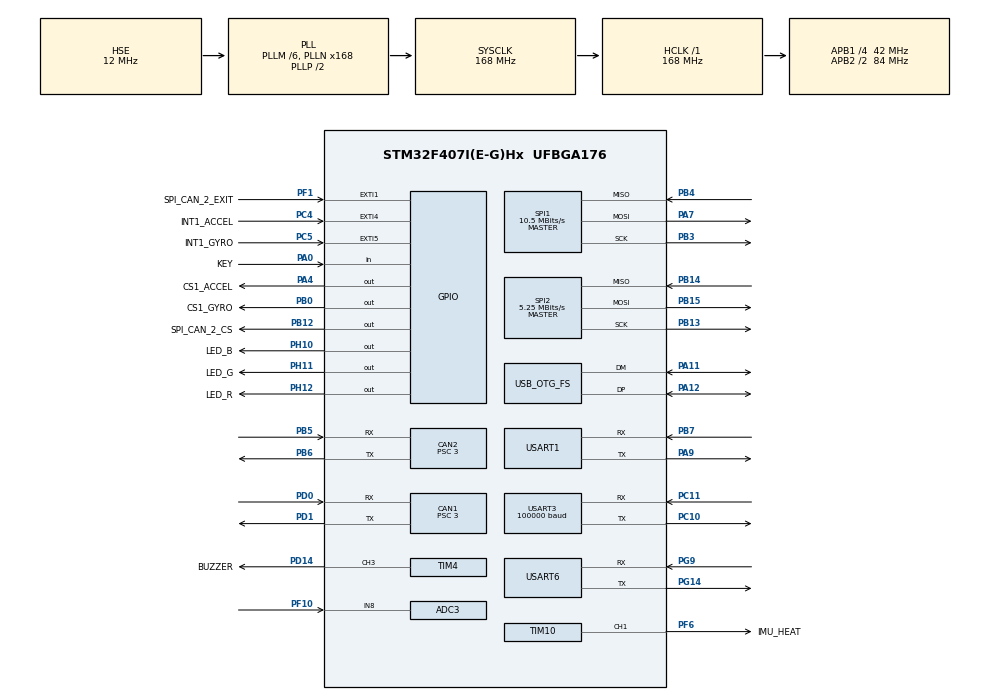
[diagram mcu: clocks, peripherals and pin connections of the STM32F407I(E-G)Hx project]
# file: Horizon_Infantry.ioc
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ADC1.Channel-0\#ChannelRegularConversion=ADC_CHANNEL_TEMPSENSOR
ADC1.NbrOfConversionFlag=1
ADC1.Rank-0\#ChannelRegularConversion=1
ADC1.SamplingTime-0\#ChannelRegularConversion=ADC_SAMPLETIME_3CYCLES
ADC1.master=1
ADC3.Channel-0\#ChannelRegularConversion=ADC_CHANNEL_8
ADC3.NbrOfConversionFlag=1
ADC3.Rank-0\#ChannelRegularConversion=1
ADC3.SamplingTime-0\#ChannelRegularConversion=ADC_SAMPLETIME_3CYCLES
CAN1.BS1=CAN_BS1_10TQ
CAN1.BS2=CAN_BS2_3TQ
CAN1.CalculateBaudRate=1000000
CAN1.CalculateTimeBit=1000
CAN1.CalculateTimeQuantum=71.42857142857143
CAN1.Prescaler=3
CAN2.BS1=CAN_BS1_10TQ
CAN2.BS2=CAN_BS2_3TQ
CAN2.CalculateBaudRate=1000000
CAN2.CalculateTimeBit=1000
CAN2.CalculateTimeQuantum=71.42857142857143
CAN2.Prescaler=3
Dma.Request0=SPI1_RX
Dma.Request1=SPI1_TX
Dma.Request2=USART1_RX
Dma.Request3=USART1_TX
Dma.Request4=USART6_RX
Dma.Request5=USART6_TX
Dma.Request6=TIM4_CH3
Dma.Request7=USART3_RX
Dma.SPI1_RX.0.Direction=DMA_PERIPH_TO_MEMORY
Dma.SPI1_RX.0.FIFOMode=DMA_FIFOMODE_DISABLE
Dma.SPI1_RX.0.Instance=DMA2_Stream2
Dma.SPI1_RX.0.MemDataAlignment=DMA_MDATAALIGN_BYTE
Dma.SPI1_RX.0.MemInc=DMA_MINC_ENABLE
Dma.SPI1_RX.0.Mode=DMA_NORMAL
Dma.SPI1_RX.0.PeriphDataAlignment=DMA_PDATAALIGN_BYTE
Dma.SPI1_RX.0.PeriphInc=DMA_PINC_DISABLE
Dma.SPI1_RX.0.Priority=DMA_PRIORITY_VERY_HIGH
Dma.SPI1_TX.1.Direction=DMA_MEMORY_TO_PERIPH
Dma.SPI1_TX.1.FIFOMode=DMA_FIFOMODE_DISABLE
Dma.SPI1_TX.1.Instance=DMA2_Stream3
Dma.SPI1_TX.1.MemDataAlignment=DMA_MDATAALIGN_BYTE
Dma.SPI1_TX.1.MemInc=DMA_MINC_ENABLE
Dma.SPI1_TX.1.Mode=DMA_NORMAL
Dma.SPI1_TX.1.PeriphDataAlignment=DMA_PDATAALIGN_BYTE
Dma.SPI1_TX.1.PeriphInc=DMA_PINC_DISABLE
Dma.SPI1_TX.1.Priority=DMA_PRIORITY_HIGH
Dma.TIM4_CH3.6.Direction=DMA_PERIPH_TO_MEMORY
Dma.TIM4_CH3.6.FIFOMode=DMA_FIFOMODE_DISABLE
Dma.TIM4_CH3.6.Instance=DMA1_Stream7
Dma.TIM4_CH3.6.MemDataAlignment=DMA_MDATAALIGN_HALFWORD
Dma.TIM4_CH3.6.MemInc=DMA_MINC_ENABLE
Dma.TIM4_CH3.6.Mode=DMA_NORMAL
Dma.TIM4_CH3.6.PeriphDataAlignment=DMA_PDATAALIGN_HALFWORD
Dma.TIM4_CH3.6.PeriphInc=DMA_PINC_DISABLE
Dma.TIM4_CH3.6.Priority=DMA_PRIORITY_LOW
Dma.USART1_RX.2.Direction=DMA_PERIPH_TO_MEMORY
Dma.USART1_RX.2.FIFOMode=DMA_FIFOMODE_DISABLE
Dma.USART1_RX.2.Instance=DMA2_Stream5
Dma.USART1_RX.2.MemDataAlignment=DMA_MDATAALIGN_BYTE
Dma.USART1_RX.2.MemInc=DMA_MINC_ENABLE
Dma.USART1_RX.2.Mode=DMA_NORMAL
Dma.USART1_RX.2.PeriphDataAlignment=DMA_PDATAALIGN_BYTE
Dma.USART1_RX.2.PeriphInc=DMA_PINC_DISABLE
Dma.USART1_RX.2.Priority=DMA_PRIORITY_LOW
Dma.USART1_TX.3.Direction=DMA_MEMORY_TO_PERIPH
Dma.USART1_TX.3.FIFOMode=DMA_FIFOMODE_DISABLE
Dma.USART1_TX.3.Instance=DMA2_Stream7
Dma.USART1_TX.3.MemDataAlignment=DMA_MDATAALIGN_BYTE
Dma.USART1_TX.3.MemInc=DMA_MINC_ENABLE
Dma.USART1_TX.3.Mode=DMA_NORMAL
Dma.USART1_TX.3.PeriphDataAlignment=DMA_PDATAALIGN_BYTE
Dma.USART1_TX.3.PeriphInc=DMA_PINC_DISABLE
Dma.USART1_TX.3.Priority=DMA_PRIORITY_LOW
Dma.USART3_RX.7.Direction=DMA_PERIPH_TO_MEMORY
Dma.USART3_RX.7.FIFOMode=DMA_FIFOMODE_DISABLE
Dma.USART3_RX.7.Instance=DMA1_Stream1
Dma.USART3_RX.7.MemDataAlignment=DMA_MDATAALIGN_BYTE
Dma.USART3_RX.7.MemInc=DMA_MINC_ENABLE
Dma.USART3_RX.7.Mode=DMA_NORMAL
Dma.USART3_RX.7.PeriphDataAlignment=DMA_PDATAALIGN_BYTE
Dma.USART3_RX.7.PeriphInc=DMA_PINC_DISABLE
Dma.USART3_RX.7.Priority=DMA_PRIORITY_LOW
Dma.USART6_RX.4.Direction=DMA_PERIPH_TO_MEMORY
Dma.USART6_RX.4.FIFOMode=DMA_FIFOMODE_DISABLE
Dma.USART6_RX.4.Instance=DMA2_Stream1
Dma.USART6_RX.4.MemDataAlignment=DMA_MDATAALIGN_BYTE
Dma.USART6_RX.4.MemInc=DMA_MINC_ENABLE
Dma.USART6_RX.4.Mode=DMA_NORMAL
Dma.USART6_RX.4.PeriphDataAlignment=DMA_PDATAALIGN_BYTE
Dma.USART6_RX.4.PeriphInc=DMA_PINC_DISABLE
Dma.USART6_RX.4.Priority=DMA_PRIORITY_LOW
Dma.USART6_TX.5.Direction=DMA_MEMORY_TO_PERIPH
Dma.USART6_TX.5.FIFOMode=DMA_FIFOMODE_DISABLE
Dma.USART6_TX.5.Instance=DMA2_Stream6
Dma.USART6_TX.5.MemDataAlignment=DMA_MDATAALIGN_BYTE
Dma.USART6_TX.5.MemInc=DMA_MINC_ENABLE
Dma.USART6_TX.5.Mode=DMA_NORMAL
Dma.USART6_TX.5.PeriphDataAlignment=DMA_PDATAALIGN_BYTE
Dma.USART6_TX.5.PeriphInc=DMA_PINC_DISABLE
Dma.USART6_TX.5.Priority=DMA_PRIORITY_LOW
FREERTOS.INCLUDE_eTaskGetState=1
FREERTOS.INCLUDE_pcTaskGetTaskName=1
FREERTOS.INCLUDE_uxTaskGetStackHighWaterMark=1
FREERTOS.INCLUDE_vTaskCleanUpResources=1
FREERTOS.INCLUDE_vTaskDelayUntil=1
FREERTOS.INCLUDE_xEventGroupSetBitFromISR=1
FREERTOS.INCLUDE_xQueueGetMutexHolder=1
FREERTOS.INCLUDE_xSemaphoreGetMutexHolder=1
FREERTOS.INCLUDE_xTaskAbortDelay=1
FREERTOS.INCLUDE_xTaskGetCurrentTaskHandle=1
FREERTOS.INCLUDE_xTaskGetHandle=1
FREERTOS.INCLUDE_xTimerPendFunctionCall=1
FREERTOS.Tasks01=defaultTask,0,128,StartDefaultTask,As weak,NULL,Dynamic,NULL,NULL;RobotUITask,-2,512,StartRobotUITask,As weak,NULL,Dynamic,NULL,NULL;MoveTask,2,512,StartMoveTask,As weak,NULL,Dynamic,NULL,NULL;DefiantTask,0,256,StartDefiantTask,As weak,NULL,Dynamic,NULL,NULL;IMUTask,2,512,StartIMUTask,As weak,NULL,Dynamic,NULL,NULL;RootTask,0,3072,StartRootTask,As weak,NULL,Dynamic,NULL,NULL
FREERTOS.configTOTAL_HEAP_SIZE=24576
FREERTOS.configUSE_TIMERS=1
Mcu.Family=STM32F4
Mcu.Name=STM32F407I(E-G)Hx
Mcu.Package=UFBGA176
NVIC.CAN1_RX0_IRQn=true\:5\:0\:false\:false\:true\:true\:true\:true\:true
NVIC.CAN2_RX0_IRQn=true\:5\:0\:false\:false\:true\:true\:true\:true\:true
NVIC.DMA1_Stream1_IRQn=true\:5\:0\:false\:false\:true\:true\:false\:true\:true
NVIC.DMA1_Stream7_IRQn=true\:5\:0\:false\:false\:true\:true\:false\:true\:true
NVIC.DMA2_Stream1_IRQn=true\:5\:0\:false\:false\:true\:true\:false\:true\:true
NVIC.DMA2_Stream2_IRQn=true\:5\:0\:false\:false\:true\:true\:false\:true\:true
NVIC.DMA2_Stream3_IRQn=true\:5\:0\:false\:false\:true\:true\:false\:true\:true
NVIC.DMA2_Stream5_IRQn=true\:5\:0\:false\:false\:true\:true\:false\:true\:true
NVIC.DMA2_Stream6_IRQn=true\:5\:0\:false\:false\:true\:true\:false\:true\:true
NVIC.DMA2_Stream7_IRQn=true\:5\:0\:false\:false\:true\:true\:false\:true\:true
NVIC.EXTI1_IRQn=true\:5\:0\:false\:false\:true\:true\:true\:true\:true
NVIC.OTG_FS_IRQn=true\:5\:0\:false\:false\:true\:true\:true\:true\:true
NVIC.PriorityGroup=NVIC_PRIORITYGROUP_4
NVIC.TIM1_UP_TIM10_IRQn=true\:5\:0\:false\:false\:true\:true\:true\:true\:true
NVIC.TIM2_IRQn=true\:15\:0\:false\:false\:true\:false\:false\:true\:true
NVIC.TIM7_IRQn=true\:5\:0\:false\:false\:true\:true\:true\:true\:true
NVIC.TimeBase=TIM2_IRQn
NVIC.TimeBaseIP=TIM2
NVIC.USART1_IRQn=true\:5\:0\:false\:false\:true\:true\:true\:true\:true
NVIC.USART3_IRQn=true\:5\:0\:false\:false\:true\:true\:true\:true\:true
NVIC.USART6_IRQn=true\:5\:0\:false\:false\:true\:true\:true\:true\:true
PA0-WKUP.GPIO_Label=KEY
PA0-WKUP.GPIO_PuPd=GPIO_PULLUP
PA0-WKUP.Signal=GPIO_Input
PA11.Mode=Device_Only
PA11.Signal=USB_OTG_FS_DM
PA12.Mode=Device_Only
PA12.Signal=USB_OTG_FS_DP
PA13.Mode=Serial_Wire
PA13.Signal=SYS_JTMS-SWDIO
PA14.Mode=Serial_Wire
PA14.Signal=SYS_JTCK-SWCLK
PA4.GPIO_Label=CS1_ACCEL
PA4.GPIO_PuPd=GPIO_PULLUP
PA4.GPIO_Speed=GPIO_SPEED_FREQ_HIGH
PA4.PinState=GPIO_PIN_SET
PA4.Signal=GPIO_Output
PA7.GPIO_PuPd=GPIO_PULLUP
PA7.Mode=Full_Duplex_Master
PA7.Signal=SPI1_MOSI
PA9.Mode=Asynchronous
PA9.Signal=USART1_TX
PB0.GPIO_Label=CS1_GYRO
PB0.GPIO_PuPd=GPIO_PULLUP
PB0.GPIO_Speed=GPIO_SPEED_FREQ_HIGH
PB0.PinState=GPIO_PIN_SET
PB0.Signal=GPIO_Output
PB12.GPIO_Label=SPI_CAN_2_CS
PB12.GPIO_PuPd=GPIO_PULLUP
PB12.GPIO_Speed=GPIO_SPEED_FREQ_MEDIUM
PB12.Signal=GPIO_Output
PB13.Mode=Full_Duplex_Master
PB13.Signal=SPI2_SCK
PB14.Mode=Full_Duplex_Master
PB14.Signal=SPI2_MISO
PB15.Mode=Full_Duplex_Master
PB15.Signal=SPI2_MOSI
PB3.GPIO_PuPd=GPIO_PULLUP
PB3.Mode=Full_Duplex_Master
PB3.Signal=SPI1_SCK
PB4.GPIO_PuPd=GPIO_PULLUP
PB4.Mode=Full_Duplex_Master
PB4.Signal=SPI1_MISO
PB5.Mode=CAN_Activate
PB5.Signal=CAN2_RX
PB6.Mode=CAN_Activate
PB6.Signal=CAN2_TX
PB7.Mode=Asynchronous
PB7.Signal=USART1_RX
PC10.Mode=Asynchronous
PC10.Signal=USART3_TX
PC11.Mode=Asynchronous
PC11.Signal=USART3_RX
PC4.GPIO_Label=INT1_ACCEL
PC4.GPIO_PuPd=GPIO_PULLUP
PC4.Signal=GPXTI4
PC5.GPIO_Label=INT1_GYRO
PC5.GPIO_PuPd=GPIO_PULLUP
PC5.Signal=GPXTI5
PD0.Mode=CAN_Activate
PD0.Signal=CAN1_RX
PD1.Mode=CAN_Activate
PD1.Signal=CAN1_TX
PD14.GPIO_Label=BUZZER
PD14.GPIO_PuPd=GPIO_PULLUP
PD14.GPIO_Speed=GPIO_SPEED_FREQ_VERY_HIGH
PD14.Signal=S_TIM4_CH3
PF1.GPIO_Label=SPI_CAN_2_EXIT
PF1.GPIO_ModeDefaultEXTI=GPIO_MODE_IT_FALLING
PF1.GPIO_PuPd=GPIO_PULLUP
PF1.Signal=GPXTI1
PF10.Mode=IN8
PF10.Signal=ADC3_IN8
PF6.GPIO_Label=IMU_HEAT
PF6.GPIO_PuPd=GPIO_PULLUP
PF6.GPIO_Speed=GPIO_SPEED_FREQ_HIGH
PF6.Signal=S_TIM10_CH1
PG14.Mode=Asynchronous
PG14.Signal=USART6_TX
PG9.Mode=Asynchronous
PG9.Signal=USART6_RX
PH0-OSC_IN.Mode=HSE-External-Oscillator
PH0-OSC_IN.Signal=RCC_OSC_IN
PH1-OSC_OUT.Mode=HSE-External-Oscillator
PH1-OSC_OUT.Signal=RCC_OSC_OUT
PH10.GPIO_Label=LED_B
PH10.Signal=GPIO_Output
PH11.GPIO_Label=LED_G
PH11.Signal=GPIO_Output
PH12.GPIO_Label=LED_R
PH12.Signal=GPIO_Output
ProjectManager.HeapSize=0x2000
ProjectManager.StackSize=0x2000
ProjectManager.TargetToolchain=MDK-ARM V5.32
RCC.48MHZClocksFreq_Value=48000000
RCC.AHBFreq_Value=168000000
RCC.APB1CLKDivider=RCC_HCLK_DIV4
RCC.APB1Freq_Value=42000000
RCC.APB1TimFreq_Value=84000000
RCC.APB2CLKDivider=RCC_HCLK_DIV2
RCC.APB2Freq_Value=84000000
RCC.APB2TimFreq_Value=168000000
RCC.CortexFreq_Value=168000000
RCC.HCLKFreq_Value=168000000
RCC.HSE_VALUE=12000000
RCC.HSI_VALUE=16000000
RCC.LSE_VALUE=32768
RCC.PLLM=6
RCC.PLLN=168
RCC.PLLQ=7
RCC.SYSCLKFreq_VALUE=168000000
RCC.SYSCLKSource=RCC_SYSCLKSOURCE_PLLCLK
RCC.VCOOutputFreq_Value=336000000
SH.S_TIM10_CH1.0=TIM10_CH1,PWM Generation1 CH1
SH.S_TIM4_CH3.0=TIM4_CH3,PWM Generation3 CH3
SPI1.BaudRatePrescaler=SPI_BAUDRATEPRESCALER_8
SPI1.CLKPhase=SPI_PHASE_2EDGE
SPI1.CLKPolarity=SPI_POLARITY_HIGH
SPI1.CalculateBaudRate=10.5 MBits/s
SPI1.Direction=SPI_DIRECTION_2LINES
SPI1.Mode=SPI_MODE_MASTER
SPI1.VirtualType=VM_MASTER
SPI2.BaudRatePrescaler=SPI_BAUDRATEPRESCALER_8
SPI2.CalculateBaudRate=5.25 MBits/s
SPI2.Direction=SPI_DIRECTION_2LINES
SPI2.Mode=SPI_MODE_MASTER
SPI2.VirtualType=VM_MASTER
STMicroelectronics.X-CUBE-AI.10.2.0.ActivationBufferSizeList=3860
STMicroelectronics.X-CUBE-AI.10.2.0.ActivationBuffers=pool0
STMicroelectronics.X-CUBE-AI.10.2.0.ActivationNames=pool0
STMicroelectronics.X-CUBE-AI.10.2.0.ActivationSizes=AI_NETWORK_DATA_ACTIVATION_1_SIZE
STMicroelectronics.X-CUBE-AI.10.2.0.HeapSize=0x2000
STMicroelectronics.X-CUBE-AI.10.2.0.InternalRamActivationBufferMaxSize=AI_NETWORK_DATA_ACTIVATIONS_SIZE
STMicroelectronics.X-CUBE-AI.10.2.0.LatestDirectoryUsed-4721cd2624cc1bda9fccaf9aca21f8bada46a2fab418390a2a6eabb3937f3483=D\:\\RoboMaster\\X_Cube_AI
STMicroelectronics.X-CUBE-AI.10.2.0.MaximumNumberOfInputLayer=1
STMicroelectronics.X-CUBE-AI.10.2.0.MaximumNumberOfOutputLayer=1
STMicroelectronics.X-CUBE-AI.10.2.0.MaximumSizeOfInputLayer=1
STMicroelectronics.X-CUBE-AI.10.2.0.MaximumSizeOfOutputLayer=1
STMicroelectronics.X-CUBE-AI.10.2.0.ModelActualCompression-4721cd2624cc1bda9fccaf9aca21f8bada46a2fab418390a2a6eabb3937f3483=0.0
STMicroelectronics.X-CUBE-AI.10.2.0.ModelCompression-4721cd2624cc1bda9fccaf9aca21f8bada46a2fab418390a2a6eabb3937f3483=High
STMicroelectronics.X-CUBE-AI.10.2.0.ModelFlashOccupation-4721cd2624cc1bda9fccaf9aca21f8bada46a2fab418390a2a6eabb3937f3483=50288
STMicroelectronics.X-CUBE-AI.10.2.0.ModelHashList=4721cd2624cc1bda9fccaf9aca21f8bada46a2fab418390a2a6eabb3937f3483
STMicroelectronics.X-CUBE-AI.10.2.0.ModelKind-4721cd2624cc1bda9fccaf9aca21f8bada46a2fab418390a2a6eabb3937f3483=ONNX
STMicroelectronics.X-CUBE-AI.10.2.0.ModelMacc-4721cd2624cc1bda9fccaf9aca21f8bada46a2fab418390a2a6eabb3937f3483=72449
STMicroelectronics.X-CUBE-AI.10.2.0.ModelName-4721cd2624cc1bda9fccaf9aca21f8bada46a2fab418390a2a6eabb3937f3483=network
STMicroelectronics.X-CUBE-AI.10.2.0.ModelNameList=network
STMicroelectronics.X-CUBE-AI.10.2.0.ModelRamOccupation-4721cd2624cc1bda9fccaf9aca21f8bada46a2fab418390a2a6eabb3937f3483=3860
STMicroelectronics.X-CUBE-AI.10.2.0.ModelStructureFile-4721cd2624cc1bda9fccaf9aca21f8bada46a2fab418390a2a6eabb3937f3483=D\:\\RoboMaster\\X_Cube_AI\\ppo_policy.onnx
STMicroelectronics.X-CUBE-AI.10.2.0.ModelType-4721cd2624cc1bda9fccaf9aca21f8bada46a2fab418390a2a6eabb3937f3483=STM32Cube.AI MCU runtime
STMicroelectronics.X-CUBE-AI.10.2.0.ReadyForCodeGeneration=true
STMicroelectronics.X-CUBE-AI.10.2.0.StackSize=0x2000
STMicroelectronics.X-CUBE-AI.10.2.0.WorkingBufferStartAddrList=0xFFFFFFFF
STMicroelectronics.X-CUBE-AI.10.2.0.XAaCUBEAaAICcArtificialOoIntelligenceJjCore=true
STMicroelectronics.X-CUBE-AI.10.2.0.copyWeightToRam=false
STMicroelectronics.X-CUBE-AI.10.2.0.customLayerConfigEnabled=false
STMicroelectronics.X-CUBE-AI.10.2.0.noOnnxIoTranspose=false
STMicroelectronics.X-CUBE-AI.10.2.0.useInputAllocation=true
STMicroelectronics.X-CUBE-AI.10.2.0.useOutputAllocation=true
TIM10.Channel=TIM_CHANNEL_1
TIM10.Period=2000-1
TIM10.Prescaler=84-1
TIM4.Channel-PWM\ Generation3\ CH3=TIM_CHANNEL_3
TIM4.Period=20999
TIM4.Prescaler=0
TIM7.Period=1000-1
TIM7.Prescaler=84-1
USART1.VirtualMode=VM_ASYNC
USART3.BaudRate=100000
USART3.Parity=PARITY_EVEN
USART3.VirtualMode=VM_ASYNC
USART3.WordLength=WORDLENGTH_9B
USART6.VirtualMode=VM_ASYNC
USB_DEVICE.CLASS_NAME_FS=CDC
USB_DEVICE.VirtualMode-CDC_FS=Cdc
USB_DEVICE.VirtualModeFS=Cdc_FS
USB_OTG_FS.VirtualMode=Device_Only
VP_ADC1_TempSens_Input.Mode=IN-TempSens
VP_CRC_VS_CRC.Mode=CRC_Activate
VP_FREERTOS_VS_CMSIS_V1.Mode=CMSIS_V1
VP_STMicroelectronics.X-CUBE-AI_VS_ArtificialOoIntelligenceJjXAaCUBEAaAI_10.2.0.Mode=ArtificialOoIntelligenceJjXAaCUBEAaAI
VP_SYS_VS_tim2.Mode=TIM2
VP_TIM10_VS_ClockSourceINT.Mode=Enable_Timer
VP_TIM4_VS_ClockSourceINT.Mode=Internal
VP_TIM7_VS_ClockSourceINT.Mode=Enable_Timer
VP_USB_DEVICE_VS_USB_DEVICE_CDC_FS.Mode=CDC_FS
board=custom

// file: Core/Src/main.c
/* USER CODE BEGIN Header */
/**
  ******************************************************************************
  * @file           : main.c
  * @brief          : Main program body
  ******************************************************************************
  * @attention
  *
  * Copyright (c) 2024 STMicroelectronics.
  * All rights reserved.
  *
  * This software is licensed under terms that can be found in the LICENSE file
  * in the root directory of this software component.
  * If no LICENSE file comes with this software, it is provided AS-IS.
  *
  ******************************************************************************
  */
/* USER CODE END Header */
#include "main.h"
#include "cmsis_os.h"
#include "adc.h"
#include "can.h"
#include "crc.h"
#include "dma.h"
#include "spi.h"
#include "tim.h"
#include "usart.h"
#include "usb_device.h"
#include "gpio.h"

/* USER CODE BEGIN Includes */
#include "chassisL.h"
/* USER CODE END Includes */

void SystemClock_Config(void);
void MX_FREERTOS_Init(void);

int main(void)
 {

  /* MCU Configuration--------------------------------------------------------*/

  /* Reset of all peripherals, Initializes the Flash interface and the Systick. */
  HAL_Init();

  /* Configure the system clock */
  SystemClock_Config();

  /* Initialize all configured peripherals */
  MX_GPIO_Init();
  MX_DMA_Init();
  MX_CAN1_Init();
  MX_CAN2_Init();
  MX_SPI1_Init();
  MX_USART1_UART_Init();
  MX_USART6_UART_Init();
  MX_CRC_Init();
  MX_TIM10_Init();
  MX_USART3_UART_Init();
  MX_TIM4_Init();
  MX_ADC1_Init();
  MX_ADC3_Init();
  MX_TIM7_Init();
  MX_SPI2_Init();

  /* Call init function for freertos objects (in freertos.c) */
  MX_FREERTOS_Init();

  /* Start scheduler */
  osKernelStart();

  /* We should never get here as control is now taken by the scheduler */
  /* Infinite loop */
  while (1)
  {

  }
}

void SystemClock_Config(void)
{
  RCC_OscInitTypeDef RCC_OscInitStruct = {0};
  RCC_ClkInitTypeDef RCC_ClkInitStruct = {0};

  /** Configure the main internal regulator output voltage
  */
  __HAL_RCC_PWR_CLK_ENABLE();
  __HAL_PWR_VOLTAGESCALING_CONFIG(PWR_REGULATOR_VOLTAGE_SCALE1);

  /** Initializes the RCC Oscillators according to the specified parameters
  * in the RCC_OscInitTypeDef structure.
  */
  RCC_OscInitStruct.OscillatorType = RCC_OSCILLATORTYPE_HSE;
  RCC_OscInitStruct.HSEState = RCC_HSE_ON;
  RCC_OscInitStruct.PLL.PLLState = RCC_PLL_ON;
  RCC_OscInitStruct.PLL.PLLSource = RCC_PLLSOURCE_HSE;
  RCC_OscInitStruct.PLL.PLLM = 6;
  RCC_OscInitStruct.PLL.PLLN = 168;
  RCC_OscInitStruct.PLL.PLLP = RCC_PLLP_DIV2;
  RCC_OscInitStruct.PLL.PLLQ = 7;
  if (HAL_RCC_OscConfig(&RCC_OscInitStruct) != HAL_OK)
  {
    Error_Handler();
  }

  /** Initializes the CPU, AHB and APB buses clocks
  */
  RCC_ClkInitStruct.ClockType = RCC_CLOCKTYPE_HCLK|RCC_CLOCKTYPE_SYSCLK
                              |RCC_CLOCKTYPE_PCLK1|RCC_CLOCKTYPE_PCLK2;
  RCC_ClkInitStruct.SYSCLKSource = RCC_SYSCLKSOURCE_PLLCLK;
  RCC_ClkInitStruct.AHBCLKDivider = RCC_SYSCLK_DIV1;
  RCC_ClkInitStruct.APB1CLKDivider = RCC_HCLK_DIV4;
  RCC_ClkInitStruct.APB2CLKDivider = RCC_HCLK_DIV2;

  if (HAL_RCC_ClockConfig(&RCC_ClkInitStruct, FLASH_LATENCY_5) != HAL_OK)
  {
    Error_Handler();
  }
}

void HAL_TIM_PeriodElapsedCallback(TIM_HandleTypeDef *htim)
{
  if (htim->Instance == TIM2) {
    HAL_IncTick();
  }
  /* USER CODE BEGIN Callback 1 */
  if (htim->Instance == TIM7) {
    Chassis_SendTorque();
  }
  /* USER CODE END Callback 1 */
}

void Error_Handler(void)
{
  __disable_irq();
  while (1)
  {
  }
}

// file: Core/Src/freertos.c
/* USER CODE BEGIN Header */
/**
  ******************************************************************************
  * File Name          : freertos.c
  * Description        : Code for freertos applications
  ******************************************************************************
  * @attention
  *
  * Copyright (c) 2024 STMicroelectronics.
  * All rights reserved.
  *
  * This software is licensed under terms that can be found in the LICENSE file
  * in the root directory of this software component.
  * If no LICENSE file comes with this software, it is provided AS-IS.
  *
  ******************************************************************************
  */
/* USER CODE END Header */

#include "FreeRTOS.h"
#include "task.h"
#include "main.h"
#include "cmsis_os.h"

osThreadId defaultTaskHandle;
osThreadId RobotUITaskHandle;
osThreadId MoveTaskHandle;
osThreadId DefiantTaskHandle;
osThreadId IMUTaskHandle;
osThreadId RootTaskHandle;

void StartDefaultTask(void const * argument);
void StartRobotUITask(void const * argument);
void StartMoveTask(void const * argument);
void StartDefiantTask(void const * argument);
void StartIMUTask(void const * argument);
void StartRootTask(void const * argument);

extern void MX_USB_DEVICE_Init(void);
void MX_FREERTOS_Init(void); /* (MISRA C 2004 rule 8.1) */

/* GetIdleTaskMemory prototype (linked to static allocation support) */
void vApplicationGetIdleTaskMemory( StaticTask_t **ppxIdleTaskTCBBuffer, StackType_t **ppxIdleTaskStackBuffer, uint32_t *pulIdleTaskStackSize );

/* GetTimerTaskMemory prototype (linked to static allocation support) */
void vApplicationGetTimerTaskMemory( StaticTask_t **ppxTimerTaskTCBBuffer, StackType_t **ppxTimerTaskStackBuffer, uint32_t *pulTimerTaskStackSize );

/* USER CODE BEGIN GET_IDLE_TASK_MEMORY */
static StaticTask_t xIdleTaskTCBBuffer;
static StackType_t xIdleStack[configMINIMAL_STACK_SIZE];

void vApplicationGetIdleTaskMemory( StaticTask_t **ppxIdleTaskTCBBuffer, StackType_t **ppxIdleTaskStackBuffer, uint32_t *pulIdleTaskStackSize )
{
  *ppxIdleTaskTCBBuffer = &xIdleTaskTCBBuffer;
  *ppxIdleTaskStackBuffer = &xIdleStack[0];
  *pulIdleTaskStackSize = configMINIMAL_STACK_SIZE;
  /* place for user code */
}
/* USER CODE END GET_IDLE_TASK_MEMORY */

/* USER CODE BEGIN GET_TIMER_TASK_MEMORY */
static StaticTask_t xTimerTaskTCBBuffer;
static StackType_t xTimerStack[configTIMER_TASK_STACK_DEPTH];

void vApplicationGetTimerTaskMemory( StaticTask_t **ppxTimerTaskTCBBuffer, StackType_t **ppxTimerTaskStackBuffer, uint32_t *pulTimerTaskStackSize )
{
  *ppxTimerTaskTCBBuffer = &xTimerTaskTCBBuffer;
  *ppxTimerTaskStackBuffer = &xTimerStack[0];
  *pulTimerTaskStackSize = configTIMER_TASK_STACK_DEPTH;
  /* place for user code */
}
/* USER CODE END GET_TIMER_TASK_MEMORY */

void MX_FREERTOS_Init(void) {

  /* Create the thread(s) */
  /* definition and creation of defaultTask */
  osThreadDef(defaultTask, StartDefaultTask, osPriorityNormal, 0, 128);
  defaultTaskHandle = osThreadCreate(osThread(defaultTask), NULL);

  /* definition and creation of RobotUITask */
  osThreadDef(RobotUITask, StartRobotUITask, osPriorityLow, 0, 512);
  RobotUITaskHandle = osThreadCreate(osThread(RobotUITask), NULL);

  /* definition and creation of MoveTask */
  osThreadDef(MoveTask, StartMoveTask, osPriorityHigh, 0, 512);
  MoveTaskHandle = osThreadCreate(osThread(MoveTask), NULL);

  /* definition and creation of DefiantTask */
  osThreadDef(DefiantTask, StartDefiantTask, osPriorityNormal, 0, 256);
  DefiantTaskHandle = osThreadCreate(osThread(DefiantTask), NULL);

  /* definition and creation of IMUTask */
  osThreadDef(IMUTask, StartIMUTask, osPriorityHigh, 0, 512);
  IMUTaskHandle = osThreadCreate(osThread(IMUTask), NULL);

  /* definition and creation of RootTask */
  osThreadDef(RootTask, StartRootTask, osPriorityNormal, 0, 3072);
  RootTaskHandle = osThreadCreate(osThread(RootTask), NULL);

}

__weak void StartDefaultTask(void const * argument)
{
  /* init code for USB_DEVICE */
  MX_USB_DEVICE_Init();
  for(;;)
  {
    osDelay(1);
  }
}

__weak void StartRobotUITask(void const * argument)
{
  for(;;)
  {
    osDelay(1);
  }
}

__weak void StartMoveTask(void const * argument)
{
  for(;;)
  {
    osDelay(1);
  }
}

__weak void StartDefiantTask(void const * argument)
{
  for(;;)
  {
    osDelay(1);
  }
}

__weak void StartIMUTask(void const * argument)
{
  for(;;)
  {
    osDelay(1);
  }
}

__weak void StartRootTask(void const * argument)
{
  for(;;)
  {
    osDelay(1);
  }
}
